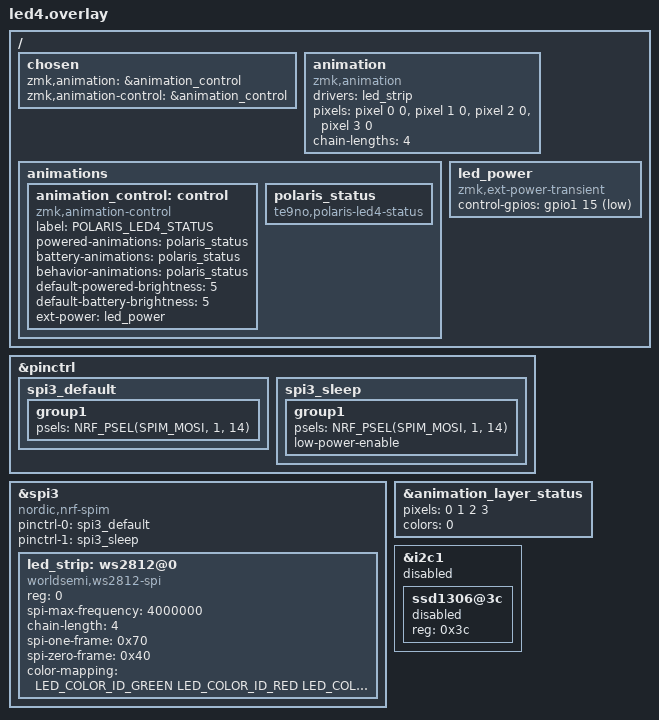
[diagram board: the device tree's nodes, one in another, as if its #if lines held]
/* Optional OLED replacement; animation design from GeaconEquinox. */
#define POLARIS_LED4 1
#ifdef POLARIS_TPD_L
#error "TPD_L and led4 both use P1.14"
#endif
#include <behaviors/animation_trigger.dtsi>
#include <behaviors/animation_control.dtsi>
#include <dt-bindings/led/led.h>
#include <dt-bindings/zmk_driver_animation/animation_control.h>
#include <dt-bindings/zmk_driver_animation/animation_trigger.h>
#include <zmk_driver_animation/animation.dtsi>
#include <zmk_driver_animation/animation_layer_status.dtsi>
#include <behaviors/rgbled_widget.dtsi>

/ {
	chosen {
		zmk,animation = &animation_control;
		zmk,animation-control = &animation_control;
	};

	animation: animation {
		compatible = "zmk,animation";
		drivers = <&led_strip>;
		pixels = <&pixel 0 0>,
		<&pixel 1 0>,
		<&pixel 2 0>,
		<&pixel 3 0>;
		chain-lengths = <4>;
	};

	animations {
        animation_control: control {
            compatible = "zmk,animation-control";
            label = "POLARIS_LED4_STATUS";
            powered-animations = <&polaris_status>;
            battery-animations = <&polaris_status>;
            behavior-animations = <&polaris_status>;
            default-powered-brightness = <5>;
            default-battery-brightness = <5>;
            ext-power = <&led_power>;
        };
        polaris_status: polaris_status {
            compatible = "te9no,polaris-led4-status";
        };
    };

	led_power:led_power {
		compatible = "zmk,ext-power-transient";
		control-gpios = <&gpio1 15 GPIO_ACTIVE_LOW>;
	};
};

//
// pinctrl for LED strip (WS2812 2020)
//

&pinctrl {
	spi3_default: spi3_default {
		group1 {
			psels = <NRF_PSEL(SPIM_MOSI, 1, 14)>;
		};
	};

	spi3_sleep: spi3_sleep {
		group1 {
			psels = <NRF_PSEL(SPIM_MOSI, 1, 14)>;
			low-power-enable;
		};
	};
};

&spi3 {
	compatible = "nordic,nrf-spim";
	status = "okay";

	pinctrl-0 = <&spi3_default>;
	pinctrl-1 = <&spi3_sleep>;
	pinctrl-names = "default", "sleep";

	led_strip: ws2812@0 {
		compatible = "worldsemi,ws2812-spi";
		reg = <0>;
		spi-max-frequency = <4000000>; // 4MHz = 0.25us

		chain-length = <4>; /* number of LEDs */
		spi-one-frame = <0x70>; // 01110000 -> T1H = 0.25 * 3 = 0.75us
		spi-zero-frame = <0x40>; // 01000000 -> T0H = 0.25us
		color-mapping = <LED_COLOR_ID_GREEN
				 LED_COLOR_ID_RED
				 LED_COLOR_ID_BLUE>;
	};
};


/* The connector cannot serve I2C OLED and LED simultaneously. */
/* Required by the pinned driver's unconditional compilation; not in the flow. */
&animation_layer_status {
    pixels = <0 1 2 3>;
    colors = <0>;
};
/ { chosen { /delete-property/ zephyr,display; }; };
&i2c1 {
    status = "disabled";
    /delete-property/ pinctrl-0;
    /delete-property/ pinctrl-1;
    /delete-property/ pinctrl-names;
    ssd1306@3c { reg = <0x3c>; status = "disabled"; };
};

